# AST1060 register map
File version: 1.0
CPU: CM4 r0p1, little endian, MPU, FPU, 4 interrupt priority bits, 256 interrupts
Registers are 32-bit, read-write, reset 0x0 unless marked. A register's access mark holds for its fields unless they carry their own. Offsets are from the block's base; lines under a group give offsets from that group; [hi:lo] are bit positions; {n}, {i} and the like mark numbered series; 'fields as' and 'values as' point back to an identical list; <NAME> marks a mode.

## Memory map
0x7E620000 fmc size 0x300
0x7E630000 spi size 0x300
0x7E640000 spi1 size 0x300 — spi interface
0x7E6D0000 hace size 0x200
0x7E6E2000 scu size 0x1000
0x7E6F2000 secure size 0x1000
0x7E780000 gpio size 0x400
0x7E780500 sgpiom size 0x100
0x7E782000 timer size 0x10
0x7E782000 timerg size 0x10
0x7E782010 timer1 size 0x10 — timer interface
0x7E782020 timer2 size 0x10 — timer interface
0x7E782040 timer3 size 0x10 — timer interface
0x7E782050 timer4 size 0x10 — timer interface
0x7E782060 timer5 size 0x10 — timer interface
0x7E782070 timer6 size 0x10 — timer interface
0x7E782080 timer7 size 0x10 — timer interface
0x7E784000 uart size 0x1000
0x7E785000 wdt size 0x80
0x7E785080 wdt1 size 0x80 — wdt interface
0x7E785100 wdt2 size 0x80 — wdt interface
0x7E785180 wdt3 size 0x80 — wdt interface
0x7E791000 spipf blocks up to offset 0x2000
0x7E792000 spipf1 blocks up to offset 0x2000 — spipf interface
0x7E793000 spipf2 blocks up to offset 0x2000 — spipf interface
0x7E794000 spipf3 blocks up to offset 0x2000 — spipf interface
0x7E79E000 uartdma size 0x1000
0x7E7A0000 i3cglobal size 0x80
0x7E7A2000 i3c size 0x1000
0x7E7A3000 i3c1 size 0x1000 — i3c interface
0x7E7A4000 i3c2 size 0x1000 — i3c interface
0x7E7A5000 i3c3 size 0x1000 — i3c interface
0x7E7B0000 i2cglobal size 0x80
0x7E7B0080 i2c size 0x1000
{0x7E7B0080+0x80*n} i2c{n} size 0x1000 (n=1..13) — i2c interface
0x7E7B0C00 i2cbuff size 0x20
{0x7E7B0C00+0x20*n} i2cbuff{n} size 0x20 (n=1..13) — i2cbuff interface
0x7E7B2000 i2cfilter size 0x200
0x7E7B2200 i2c_filter_thr size 0x100
0x7E7B2300 i2c_filter_thr1 size 0x100 — i2c_filter_thr interface
0x7E7B2400 i2c_filter_thr2 size 0x100 — i2c_filter_thr interface
0x7E7B2500 i2c_filter_thr3 size 0x100 — i2c_filter_thr interface

## Interrupts
4 hace
8 uart
11 gpio
12 scu
16 timer
17 timer1
18 timer2
19 timer3
20 timer4
21 timer5
22 timer6
23 timer7
24 wdt
39 fmc
51 sgpiom
56 uartdma
65 spi
66 spi1
88 spipf1
89 spipf2
90 spipf3
102 i3c
103 i3c1
104 i3c2
105 i3c3
110 i2c
{n+110} i2c{n} (n=1..13)
127 i2cfilter

## i3cglobal
Base 0x7E7A0000
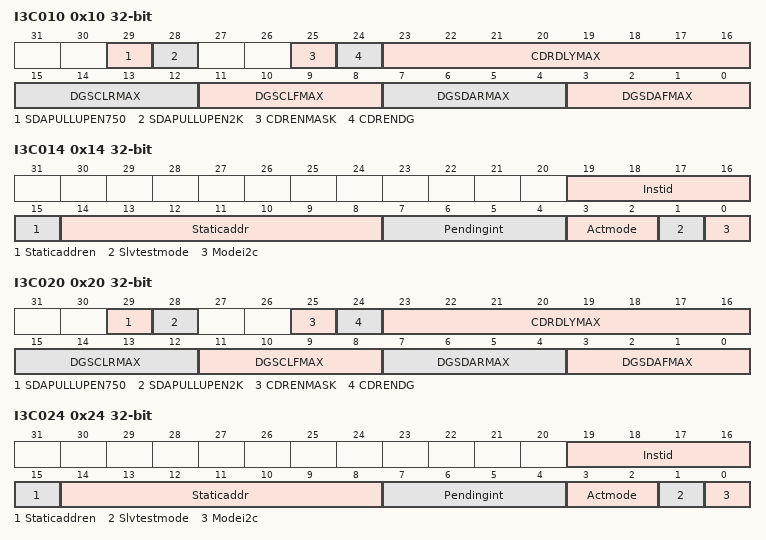
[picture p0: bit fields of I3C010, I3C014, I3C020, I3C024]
0x10 I3C010 — I3C1Reg0
  [29] SDAPULLUPEN750, [28] SDAPULLUPEN2K, [25] CDRENMASK, [24] CDRENDG, [23:16] CDRDLYMAX, [15:12] DGSCLRMAX, [11:8] DGSCLFMAX, [7:4] DGSDARMAX, [3:0] DGSDAFMAX
0x14 I3C014 — I3C1Reg1
  [19:16] Instid, [15] Staticaddren, [14:8] Staticaddr, [7:4] Pendingint, [3:2] Actmode, [1] Slvtestmode, [0] Modei2c
0x18 MI3C18 — I3C1Dbg1 (Master)
  [31:0] MasterModeDebugSigs ro — - Master Mode Debug Signals
  [31:0] SlaveModeDebugSigs ro — - Slave Mode Debug Signals
{0xC+0x10*i} MI3C{i}C (reset mask 0xFF0001) (i=1..6) — I3C{i}Dbg2 (Master)
  [23] Sdain ro — SDA input signal.
  [23] Sdain1 ro — SDA input signal.
  [22] Sdapullupen ro — SDA pullup enable signal.
  [22] Sdapullupen1 ro — SDA pullup enable signal.
  [21] Sdaout ro — SDA output signal.
  [21] Sdaout1 ro — SDA output signal.
  [20] Sdaoe ro — SDA output enable signal.
  [20] Sdaoe1 ro — SDA output enable signal.
  [19] Sclin ro — SCL input signal.
  [19] Sclin1 ro — SCL input signal.
  [18] Sclpullupen ro — SCL pullup enable signal.
  [18] Sclpullupen1 ro — SCL pullup enable signal.
  [17] Sclout ro — SCL output signal.
  [17] Sclout1 ro — SCL output signal.
  [16] Scloe ro — SCL output enable signal.
  [16] Scloe1 ro — SCL output enable signal.
  [11:8] Debug4340 ro — Indicates Slave Command TID.
  [7:3] Debug3935 ro — Indicates Slave Transfer State.
  [2] Debug34 ro — Indicates Periodic Poll slot tick change pulse.
  [1] Debug33 ro — Indicates if Periodic Poll command is in progress.
  [0] Debug32 ro — Indicates the Enable status of the controller.
  [0] Debug321 ro — Indicates the Enable status of the controller.
0x20 I3C020 — I3C2Reg0
  fields as I3C010
0x24 I3C024 — I3C2Reg1
  fields as I3C014
0x28 MI3C28 — I3C2Dbg1 (Master)
  fields as MI3C18
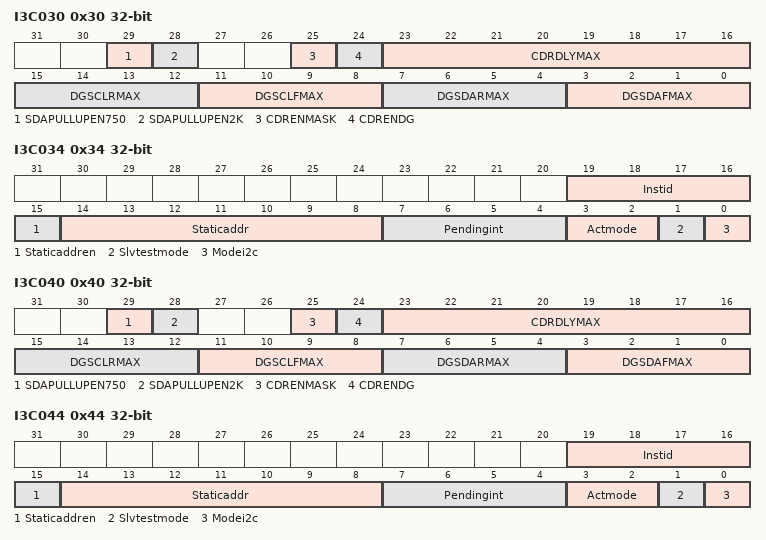
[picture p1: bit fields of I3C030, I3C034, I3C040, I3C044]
0x30 I3C030 — I3C3Reg0
  fields as I3C010
0x34 I3C034 — I3C3Reg1
  fields as I3C014
0x38 MI3C38 — I3C3Dbg1 (Master)
  fields as MI3C18
0x40 I3C040 — I3C4Reg0
  fields as I3C010
0x44 I3C044 — I3C4Reg1
  fields as I3C014
0x48 MI3C48 — I3C4Dbg1 (Master)
  fields as MI3C18
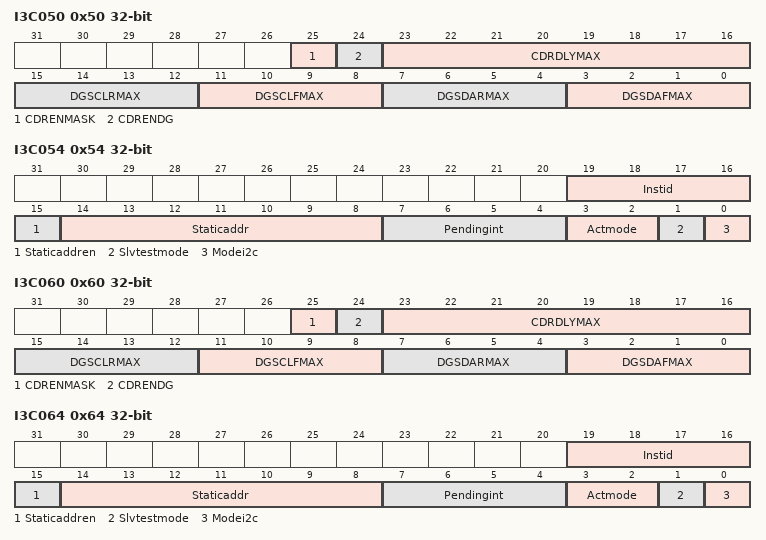
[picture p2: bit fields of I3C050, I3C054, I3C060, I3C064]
0x50 I3C050 — I3C5Reg0
  [25] CDRENMASK, [24] CDRENDG, [23:16] CDRDLYMAX, [15:12] DGSCLRMAX, [11:8] DGSCLFMAX, [7:4] DGSDARMAX, [3:0] DGSDAFMAX
0x54 I3C054 — I3C5Reg1
  fields as I3C014
0x58 MI3C58 — I3C5Dbg1 (Master)
  fields as MI3C18
0x60 I3C060 — I3C6Reg0
  fields as I3C050
0x64 I3C064 — I3C6Reg1
  fields as I3C014
0x68 MI3C68 — I3C6Dbg1 (Master)
  fields as MI3C18

## Notices in the file
Copyright (c) 2025 ASPEED Technology.
SPDX-License-Identifier: Apache-2.0
Licensed under the Apache License, Version 2.0 (the "License");
you may not use this file except in compliance with the License.
You may obtain a copy of the License at
http://www.apache.org/licenses/LICENSE-2.0
Unless required by applicable law or agreed to in writing, software
distributed under the License is distributed on an "AS IS" BASIS,
WITHOUT WARRANTIES OR CONDITIONS OF ANY KIND, either express or
implied. See the License for the specific language governing
permissions and limitations under the License.
